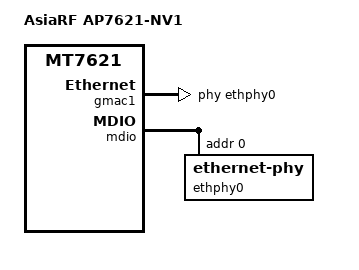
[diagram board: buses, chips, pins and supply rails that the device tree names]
// SPDX-License-Identifier: GPL-2.0-or-later OR MIT

#include "mt7621_asiarf_ap7621.dtsi"

/ {
	compatible = "asiarf,ap7621-nv1", "mediatek,mt7621-soc";
	model = "AsiaRF AP7621-NV1";
};

&gmac1 {
	status = "okay";
	label = "wan";
	phy-handle = <&ethphy0>;

	nvmem-cells = <&macaddr_factory_e000>;
	nvmem-cell-names = "mac-address";
	mac-address-increment = <1>;
};

&mdio {
	ethphy0: ethernet-phy@0 {
		reg = <0>;
	};
};

&switch0 {
	ports {
		port@2 {
			status = "okay";
			label = "lan1";
		};

		port@3 {
			status = "okay";
			label = "lan2";
		};
	};
};
